# CTRL_MODULE_CORE register map
Vendor: Texas Instruments
Registers are 32-bit, access per field, reset 0x0 unless marked. A register's access mark holds for its fields unless they carry their own. Offsets are as the file gives them; [hi:lo] are bit positions.

## CTRL_MODULE_CORE (part 3 of 12)
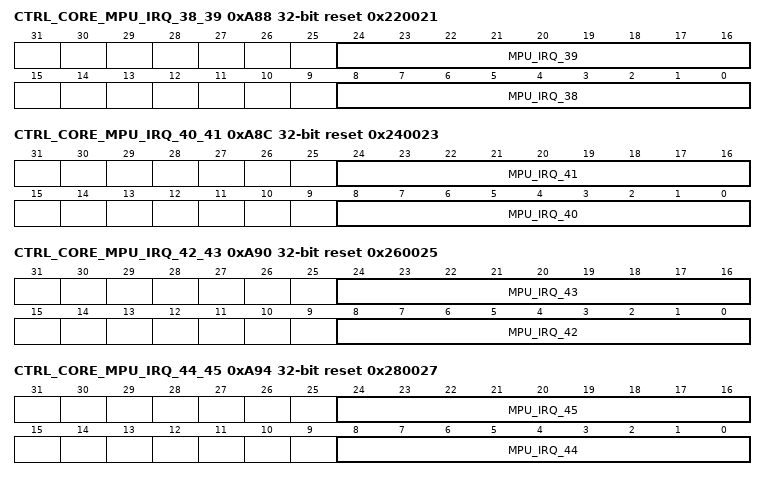
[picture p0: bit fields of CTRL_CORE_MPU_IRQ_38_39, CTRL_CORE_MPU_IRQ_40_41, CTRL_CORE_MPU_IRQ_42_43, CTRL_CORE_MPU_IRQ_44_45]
0xA88 CTRL_CORE_MPU_IRQ_38_39 reset 0x220021
  [24:16] MPU_IRQ_39 rw, [8:0] MPU_IRQ_38 rw
0xA8C CTRL_CORE_MPU_IRQ_40_41 reset 0x240023
  [24:16] MPU_IRQ_41 rw, [8:0] MPU_IRQ_40 rw
0xA90 CTRL_CORE_MPU_IRQ_42_43 reset 0x260025
  [24:16] MPU_IRQ_43 rw, [8:0] MPU_IRQ_42 rw
0xA94 CTRL_CORE_MPU_IRQ_44_45 reset 0x280027
  [24:16] MPU_IRQ_45 rw, [8:0] MPU_IRQ_44 rw
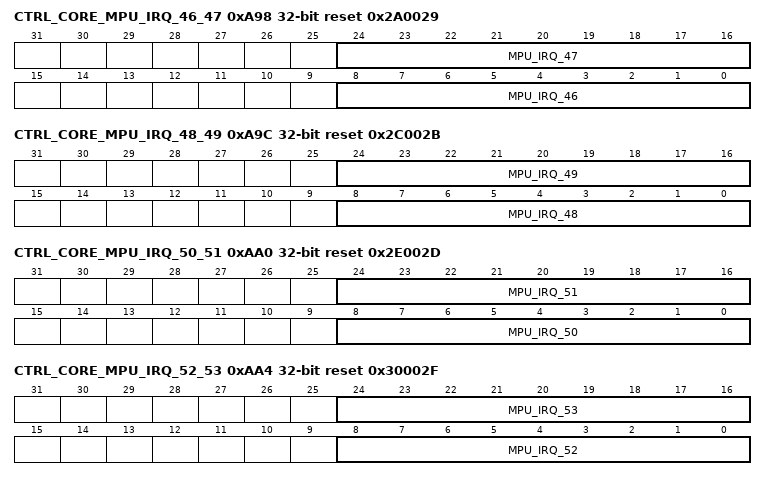
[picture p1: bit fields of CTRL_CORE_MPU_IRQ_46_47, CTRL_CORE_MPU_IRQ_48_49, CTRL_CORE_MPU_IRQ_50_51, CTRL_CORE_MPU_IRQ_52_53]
0xA98 CTRL_CORE_MPU_IRQ_46_47 reset 0x2A0029
  [24:16] MPU_IRQ_47 rw, [8:0] MPU_IRQ_46 rw
0xA9C CTRL_CORE_MPU_IRQ_48_49 reset 0x2C002B
  [24:16] MPU_IRQ_49 rw, [8:0] MPU_IRQ_48 rw
0xAA0 CTRL_CORE_MPU_IRQ_50_51 reset 0x2E002D
  [24:16] MPU_IRQ_51 rw, [8:0] MPU_IRQ_50 rw
0xAA4 CTRL_CORE_MPU_IRQ_52_53 reset 0x30002F
  [24:16] MPU_IRQ_53 rw, [8:0] MPU_IRQ_52 rw
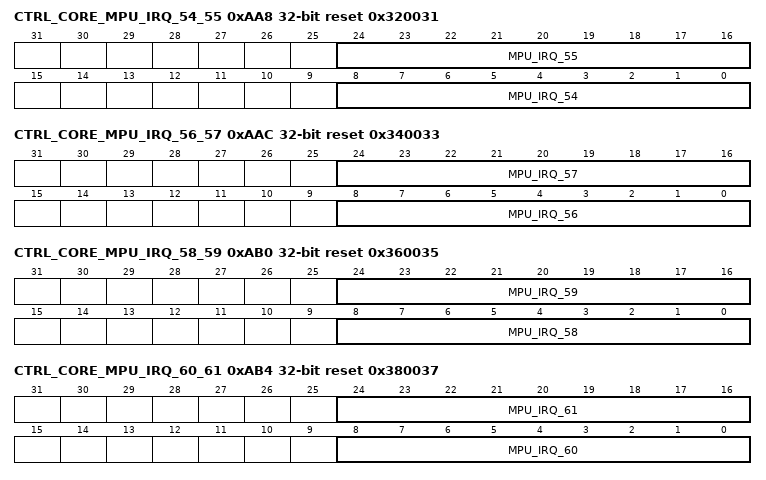
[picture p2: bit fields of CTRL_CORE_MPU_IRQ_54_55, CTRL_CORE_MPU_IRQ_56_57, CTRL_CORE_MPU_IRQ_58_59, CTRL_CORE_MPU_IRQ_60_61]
0xAA8 CTRL_CORE_MPU_IRQ_54_55 reset 0x320031
  [24:16] MPU_IRQ_55 rw, [8:0] MPU_IRQ_54 rw
0xAAC CTRL_CORE_MPU_IRQ_56_57 reset 0x340033
  [24:16] MPU_IRQ_57 rw, [8:0] MPU_IRQ_56 rw
0xAB0 CTRL_CORE_MPU_IRQ_58_59 reset 0x360035
  [24:16] MPU_IRQ_59 rw, [8:0] MPU_IRQ_58 rw
0xAB4 CTRL_CORE_MPU_IRQ_60_61 reset 0x380037
  [24:16] MPU_IRQ_61 rw, [8:0] MPU_IRQ_60 rw
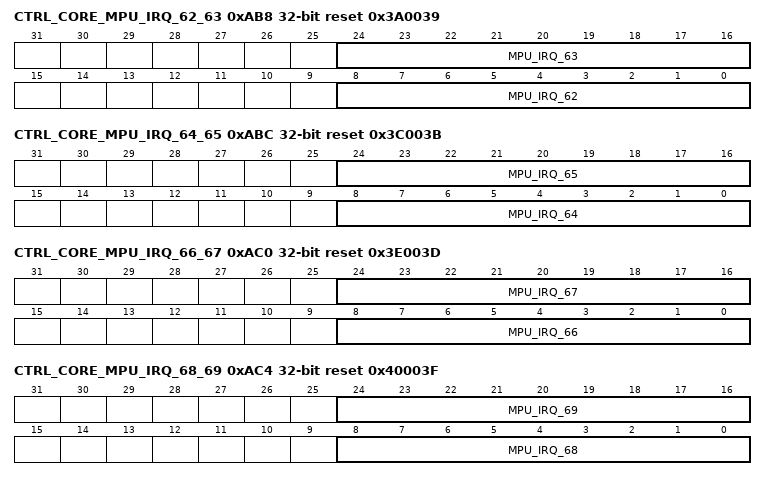
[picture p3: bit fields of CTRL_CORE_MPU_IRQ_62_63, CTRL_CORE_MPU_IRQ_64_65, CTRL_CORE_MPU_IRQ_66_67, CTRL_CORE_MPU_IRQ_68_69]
0xAB8 CTRL_CORE_MPU_IRQ_62_63 reset 0x3A0039
  [24:16] MPU_IRQ_63 rw, [8:0] MPU_IRQ_62 rw
0xABC CTRL_CORE_MPU_IRQ_64_65 reset 0x3C003B
  [24:16] MPU_IRQ_65 rw, [8:0] MPU_IRQ_64 rw
0xAC0 CTRL_CORE_MPU_IRQ_66_67 reset 0x3E003D
  [24:16] MPU_IRQ_67 rw, [8:0] MPU_IRQ_66 rw
0xAC4 CTRL_CORE_MPU_IRQ_68_69 reset 0x40003F
  [24:16] MPU_IRQ_69 rw, [8:0] MPU_IRQ_68 rw
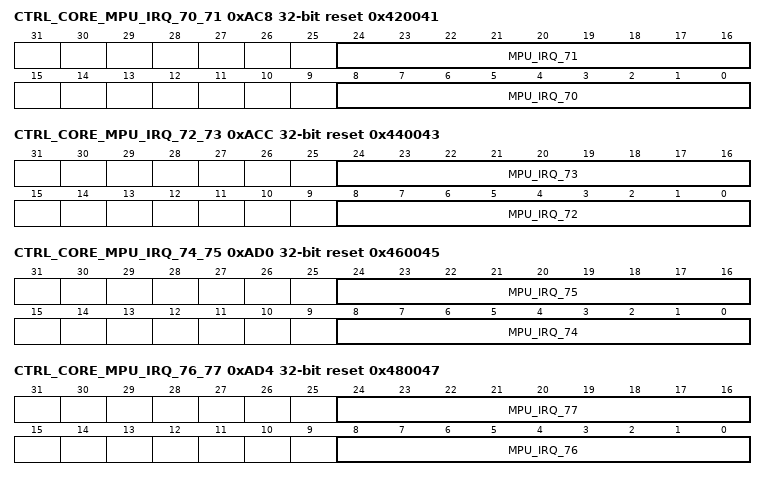
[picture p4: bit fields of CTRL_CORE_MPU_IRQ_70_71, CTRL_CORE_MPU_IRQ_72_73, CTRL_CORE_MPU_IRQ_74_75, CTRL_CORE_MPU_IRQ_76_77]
0xAC8 CTRL_CORE_MPU_IRQ_70_71 reset 0x420041
  [24:16] MPU_IRQ_71 rw, [8:0] MPU_IRQ_70 rw
0xACC CTRL_CORE_MPU_IRQ_72_73 reset 0x440043
  [24:16] MPU_IRQ_73 rw, [8:0] MPU_IRQ_72 rw
0xAD0 CTRL_CORE_MPU_IRQ_74_75 reset 0x460045
  [24:16] MPU_IRQ_75 rw, [8:0] MPU_IRQ_74 rw
0xAD4 CTRL_CORE_MPU_IRQ_76_77 reset 0x480047
  [24:16] MPU_IRQ_77 rw, [8:0] MPU_IRQ_76 rw
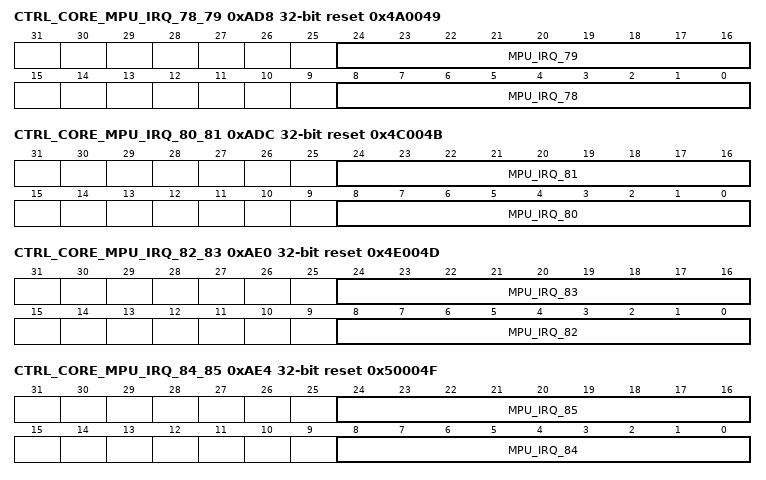
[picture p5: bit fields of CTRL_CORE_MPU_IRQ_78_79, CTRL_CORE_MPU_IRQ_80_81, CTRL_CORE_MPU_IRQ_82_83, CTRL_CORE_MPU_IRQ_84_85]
0xAD8 CTRL_CORE_MPU_IRQ_78_79 reset 0x4A0049
  [24:16] MPU_IRQ_79 rw, [8:0] MPU_IRQ_78 rw
0xADC CTRL_CORE_MPU_IRQ_80_81 reset 0x4C004B
  [24:16] MPU_IRQ_81 rw, [8:0] MPU_IRQ_80 rw
0xAE0 CTRL_CORE_MPU_IRQ_82_83 reset 0x4E004D
  [24:16] MPU_IRQ_83 rw, [8:0] MPU_IRQ_82 rw
0xAE4 CTRL_CORE_MPU_IRQ_84_85 reset 0x50004F
  [24:16] MPU_IRQ_85 rw, [8:0] MPU_IRQ_84 rw
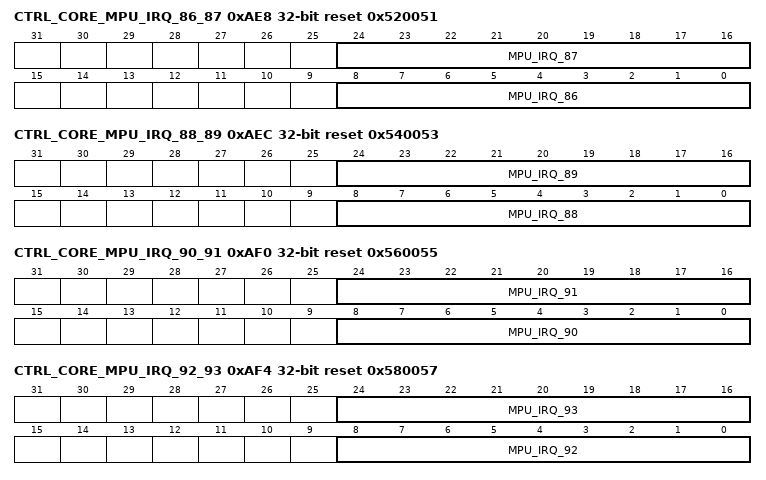
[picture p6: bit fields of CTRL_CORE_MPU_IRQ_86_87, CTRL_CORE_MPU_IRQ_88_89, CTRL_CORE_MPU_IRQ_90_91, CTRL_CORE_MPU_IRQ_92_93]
0xAE8 CTRL_CORE_MPU_IRQ_86_87 reset 0x520051
  [24:16] MPU_IRQ_87 rw, [8:0] MPU_IRQ_86 rw
0xAEC CTRL_CORE_MPU_IRQ_88_89 reset 0x540053
  [24:16] MPU_IRQ_89 rw, [8:0] MPU_IRQ_88 rw
0xAF0 CTRL_CORE_MPU_IRQ_90_91 reset 0x560055
  [24:16] MPU_IRQ_91 rw, [8:0] MPU_IRQ_90 rw
0xAF4 CTRL_CORE_MPU_IRQ_92_93 reset 0x580057
  [24:16] MPU_IRQ_93 rw, [8:0] MPU_IRQ_92 rw
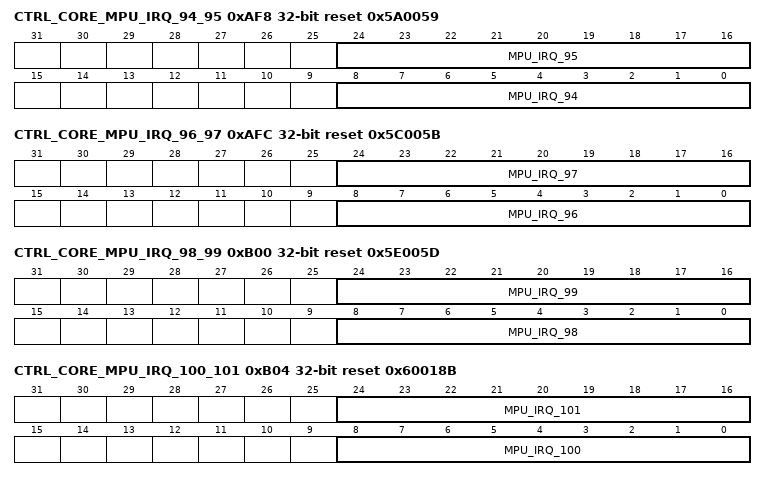
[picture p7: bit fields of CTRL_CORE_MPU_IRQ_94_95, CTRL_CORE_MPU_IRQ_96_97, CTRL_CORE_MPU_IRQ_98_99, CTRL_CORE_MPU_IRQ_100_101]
0xAF8 CTRL_CORE_MPU_IRQ_94_95 reset 0x5A0059
  [24:16] MPU_IRQ_95 rw, [8:0] MPU_IRQ_94 rw
0xAFC CTRL_CORE_MPU_IRQ_96_97 reset 0x5C005B
  [24:16] MPU_IRQ_97 rw, [8:0] MPU_IRQ_96 rw
0xB00 CTRL_CORE_MPU_IRQ_98_99 reset 0x5E005D
  [24:16] MPU_IRQ_99 rw, [8:0] MPU_IRQ_98 rw
0xB04 CTRL_CORE_MPU_IRQ_100_101 reset 0x60018B
  [24:16] MPU_IRQ_101 rw, [8:0] MPU_IRQ_100 rw
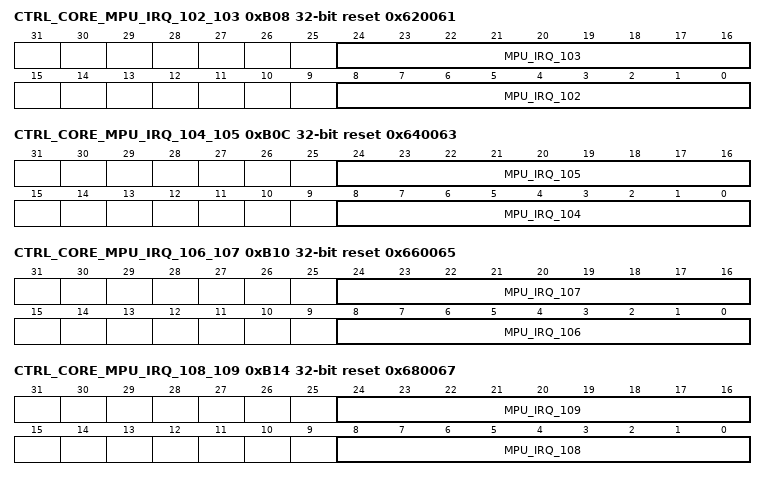
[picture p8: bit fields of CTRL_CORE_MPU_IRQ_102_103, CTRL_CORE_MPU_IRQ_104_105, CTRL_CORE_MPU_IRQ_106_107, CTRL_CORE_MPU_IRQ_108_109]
0xB08 CTRL_CORE_MPU_IRQ_102_103 reset 0x620061
  [24:16] MPU_IRQ_103 rw, [8:0] MPU_IRQ_102 rw
0xB0C CTRL_CORE_MPU_IRQ_104_105 reset 0x640063
  [24:16] MPU_IRQ_105 rw, [8:0] MPU_IRQ_104 rw
0xB10 CTRL_CORE_MPU_IRQ_106_107 reset 0x660065
  [24:16] MPU_IRQ_107 rw, [8:0] MPU_IRQ_106 rw
0xB14 CTRL_CORE_MPU_IRQ_108_109 reset 0x680067
  [24:16] MPU_IRQ_109 rw, [8:0] MPU_IRQ_108 rw
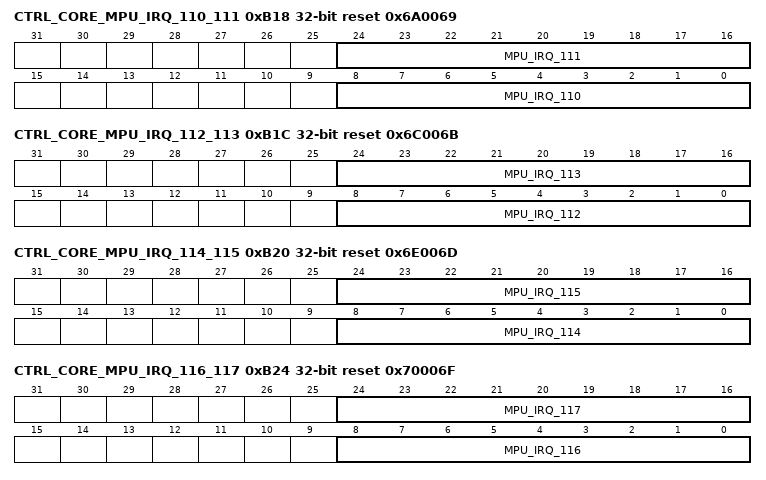
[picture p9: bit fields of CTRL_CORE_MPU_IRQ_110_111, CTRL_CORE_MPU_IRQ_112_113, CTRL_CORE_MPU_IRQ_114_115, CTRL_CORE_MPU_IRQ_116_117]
0xB18 CTRL_CORE_MPU_IRQ_110_111 reset 0x6A0069
  [24:16] MPU_IRQ_111 rw, [8:0] MPU_IRQ_110 rw
0xB1C CTRL_CORE_MPU_IRQ_112_113 reset 0x6C006B
  [24:16] MPU_IRQ_113 rw, [8:0] MPU_IRQ_112 rw
0xB20 CTRL_CORE_MPU_IRQ_114_115 reset 0x6E006D
  [24:16] MPU_IRQ_115 rw, [8:0] MPU_IRQ_114 rw
0xB24 CTRL_CORE_MPU_IRQ_116_117 reset 0x70006F
  [24:16] MPU_IRQ_117 rw, [8:0] MPU_IRQ_116 rw
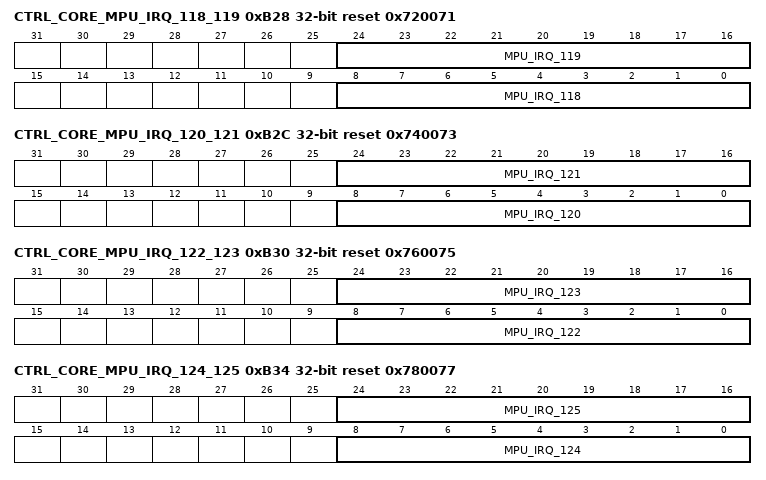
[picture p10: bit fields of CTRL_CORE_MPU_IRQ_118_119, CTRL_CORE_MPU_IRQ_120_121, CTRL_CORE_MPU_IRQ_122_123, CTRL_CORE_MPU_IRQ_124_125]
0xB28 CTRL_CORE_MPU_IRQ_118_119 reset 0x720071
  [24:16] MPU_IRQ_119 rw, [8:0] MPU_IRQ_118 rw
0xB2C CTRL_CORE_MPU_IRQ_120_121 reset 0x740073
  [24:16] MPU_IRQ_121 rw, [8:0] MPU_IRQ_120 rw
0xB30 CTRL_CORE_MPU_IRQ_122_123 reset 0x760075
  [24:16] MPU_IRQ_123 rw, [8:0] MPU_IRQ_122 rw
0xB34 CTRL_CORE_MPU_IRQ_124_125 reset 0x780077
  [24:16] MPU_IRQ_125 rw, [8:0] MPU_IRQ_124 rw
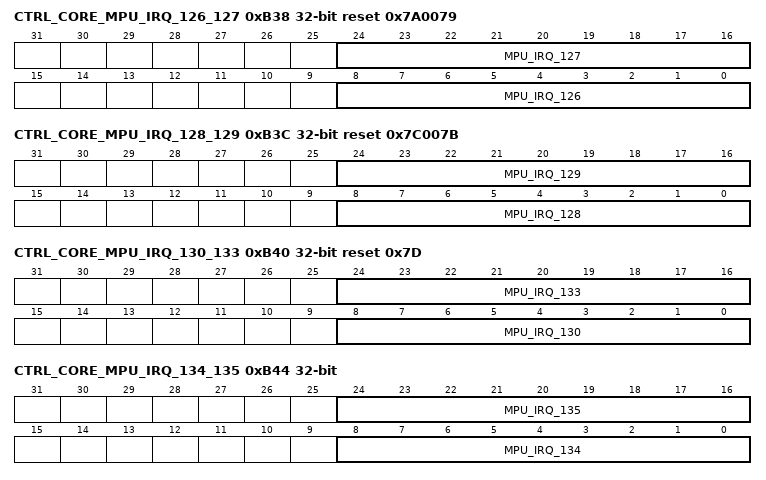
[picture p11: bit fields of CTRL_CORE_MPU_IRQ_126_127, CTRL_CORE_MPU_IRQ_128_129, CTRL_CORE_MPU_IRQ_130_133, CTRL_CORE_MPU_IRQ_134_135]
0xB38 CTRL_CORE_MPU_IRQ_126_127 reset 0x7A0079
  [24:16] MPU_IRQ_127 rw, [8:0] MPU_IRQ_126 rw
0xB3C CTRL_CORE_MPU_IRQ_128_129 reset 0x7C007B
  [24:16] MPU_IRQ_129 rw, [8:0] MPU_IRQ_128 rw
0xB40 CTRL_CORE_MPU_IRQ_130_133 reset 0x7D
  [24:16] MPU_IRQ_133 rw, [8:0] MPU_IRQ_130 rw
0xB44 CTRL_CORE_MPU_IRQ_134_135
  [24:16] MPU_IRQ_135 rw, [8:0] MPU_IRQ_134 rw
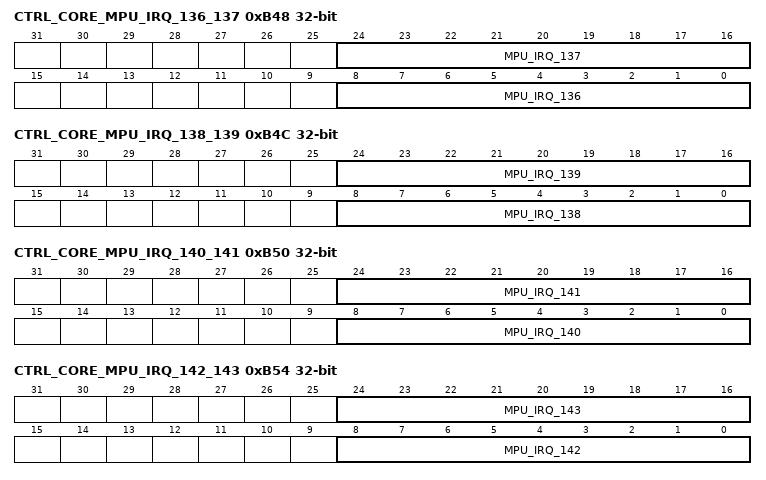
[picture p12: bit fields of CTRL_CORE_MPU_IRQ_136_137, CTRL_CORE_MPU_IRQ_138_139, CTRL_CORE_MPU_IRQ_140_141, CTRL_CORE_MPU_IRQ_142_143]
0xB48 CTRL_CORE_MPU_IRQ_136_137
  [24:16] MPU_IRQ_137 rw, [8:0] MPU_IRQ_136 rw
0xB4C CTRL_CORE_MPU_IRQ_138_139
  [24:16] MPU_IRQ_139 rw, [8:0] MPU_IRQ_138 rw
0xB50 CTRL_CORE_MPU_IRQ_140_141
  [24:16] MPU_IRQ_141 rw, [8:0] MPU_IRQ_140 rw
0xB54 CTRL_CORE_MPU_IRQ_142_143
  [24:16] MPU_IRQ_143 rw, [8:0] MPU_IRQ_142 rw
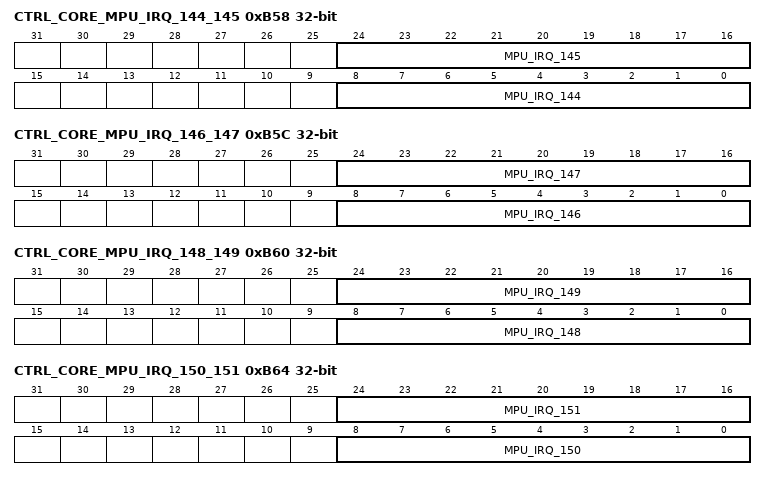
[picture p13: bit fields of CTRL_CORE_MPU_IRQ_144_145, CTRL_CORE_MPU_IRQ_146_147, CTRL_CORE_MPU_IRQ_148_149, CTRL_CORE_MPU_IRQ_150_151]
0xB58 CTRL_CORE_MPU_IRQ_144_145
  [24:16] MPU_IRQ_145 rw, [8:0] MPU_IRQ_144 rw
0xB5C CTRL_CORE_MPU_IRQ_146_147
  [24:16] MPU_IRQ_147 rw, [8:0] MPU_IRQ_146 rw
0xB60 CTRL_CORE_MPU_IRQ_148_149
  [24:16] MPU_IRQ_149 rw, [8:0] MPU_IRQ_148 rw
0xB64 CTRL_CORE_MPU_IRQ_150_151
  [24:16] MPU_IRQ_151 rw, [8:0] MPU_IRQ_150 rw
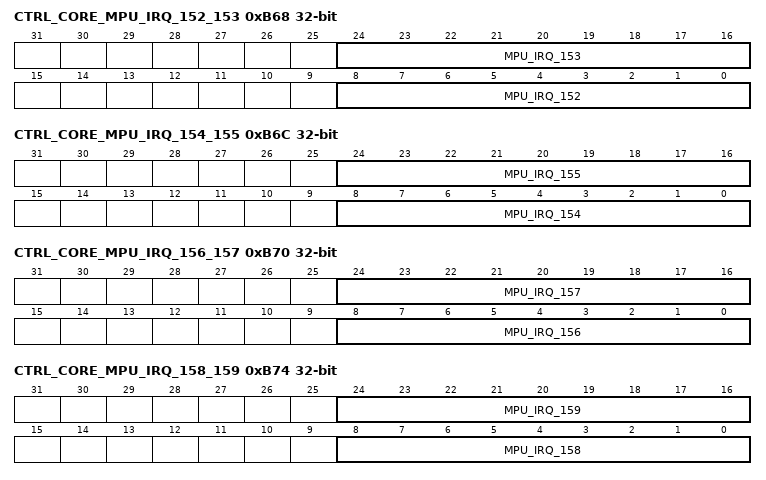
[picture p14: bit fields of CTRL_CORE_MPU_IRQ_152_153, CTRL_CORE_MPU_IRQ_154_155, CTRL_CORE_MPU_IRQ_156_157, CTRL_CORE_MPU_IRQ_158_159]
0xB68 CTRL_CORE_MPU_IRQ_152_153
  [24:16] MPU_IRQ_153 rw, [8:0] MPU_IRQ_152 rw
0xB6C CTRL_CORE_MPU_IRQ_154_155
  [24:16] MPU_IRQ_155 rw, [8:0] MPU_IRQ_154 rw
0xB70 CTRL_CORE_MPU_IRQ_156_157
  [24:16] MPU_IRQ_157 rw, [8:0] MPU_IRQ_156 rw
0xB74 CTRL_CORE_MPU_IRQ_158_159
  [24:16] MPU_IRQ_159 rw, [8:0] MPU_IRQ_158 rw
0xB78 CTRL_CORE_DMA_SYSTEM_DREQ_0_1 reset 0x20001
  [23:16] DMA_SYSTEM_DREQ_1_IRQ_1 rw, [7:0] DMA_SYSTEM_DREQ_0_IRQ_0 rw
0xB7C CTRL_CORE_DMA_SYSTEM_DREQ_2_3 reset 0x40003
  [23:16] DMA_SYSTEM_DREQ_3_IRQ_3 rw, [7:0] DMA_SYSTEM_DREQ_2_IRQ_2 rw
0xB80 CTRL_CORE_DMA_SYSTEM_DREQ_4_5 reset 0x60005
  [23:16] DMA_SYSTEM_DREQ_5_IRQ_5 rw, [7:0] DMA_SYSTEM_DREQ_4_IRQ_4 rw
0xB84 CTRL_CORE_DMA_SYSTEM_DREQ_6_7 reset 0x80007
  [23:16] DMA_SYSTEM_DREQ_7_IRQ_7 rw, [7:0] DMA_SYSTEM_DREQ_6_IRQ_6 rw
0xB88 CTRL_CORE_DMA_SYSTEM_DREQ_8_9 reset 0xA0009
  [23:16] DMA_SYSTEM_DREQ_9_IRQ_9 rw, [7:0] DMA_SYSTEM_DREQ_8_IRQ_8 rw
0xB8C CTRL_CORE_DMA_SYSTEM_DREQ_10_11 reset 0xC000B
  [23:16] DMA_SYSTEM_DREQ_11_IRQ_11 rw, [7:0] DMA_SYSTEM_DREQ_10_IRQ_10 rw
0xB90 CTRL_CORE_DMA_SYSTEM_DREQ_12_13 reset 0xE000D
  [23:16] DMA_SYSTEM_DREQ_13_IRQ_13 rw, [7:0] DMA_SYSTEM_DREQ_12_IRQ_12 rw
0xB94 CTRL_CORE_DMA_SYSTEM_DREQ_14_15 reset 0x10000F
  [23:16] DMA_SYSTEM_DREQ_15_IRQ_15 rw, [7:0] DMA_SYSTEM_DREQ_14_IRQ_14 rw
0xB98 CTRL_CORE_DMA_SYSTEM_DREQ_16_17 reset 0x120011
  [23:16] DMA_SYSTEM_DREQ_17_IRQ_17 rw, [7:0] DMA_SYSTEM_DREQ_16_IRQ_16 rw
0xB9C CTRL_CORE_DMA_SYSTEM_DREQ_18_19 reset 0x140013
  [23:16] DMA_SYSTEM_DREQ_19_IRQ_19 rw, [7:0] DMA_SYSTEM_DREQ_18_IRQ_18 rw
0xBA0 CTRL_CORE_DMA_SYSTEM_DREQ_20_21 reset 0x160015
  [23:16] DMA_SYSTEM_DREQ_21_IRQ_21 rw, [7:0] DMA_SYSTEM_DREQ_20_IRQ_20 rw
0xBA4 CTRL_CORE_DMA_SYSTEM_DREQ_22_23 reset 0x180017
  [23:16] DMA_SYSTEM_DREQ_23_IRQ_23 rw, [7:0] DMA_SYSTEM_DREQ_22_IRQ_22 rw
0xBA8 CTRL_CORE_DMA_SYSTEM_DREQ_24_25 reset 0x1A0019
  [23:16] DMA_SYSTEM_DREQ_25_IRQ_25 rw, [7:0] DMA_SYSTEM_DREQ_24_IRQ_24 rw
0xBAC CTRL_CORE_DMA_SYSTEM_DREQ_26_27 reset 0x1C001B
  [23:16] DMA_SYSTEM_DREQ_27_IRQ_27 rw, [7:0] DMA_SYSTEM_DREQ_26_IRQ_26 rw
0xBB0 CTRL_CORE_DMA_SYSTEM_DREQ_28_29 reset 0x1E001D
  [23:16] DMA_SYSTEM_DREQ_29_IRQ_29 rw, [7:0] DMA_SYSTEM_DREQ_28_IRQ_28 rw
0xBB4 CTRL_CORE_DMA_SYSTEM_DREQ_30_31 reset 0x20001F
  [23:16] DMA_SYSTEM_DREQ_31_IRQ_31 rw, [7:0] DMA_SYSTEM_DREQ_30_IRQ_30 rw
0xBB8 CTRL_CORE_DMA_SYSTEM_DREQ_32_33 reset 0x220021
  [23:16] DMA_SYSTEM_DREQ_33_IRQ_33 rw, [7:0] DMA_SYSTEM_DREQ_32_IRQ_32 rw
0xBBC CTRL_CORE_DMA_SYSTEM_DREQ_34_35 reset 0x240023
  [23:16] DMA_SYSTEM_DREQ_35_IRQ_35 rw, [7:0] DMA_SYSTEM_DREQ_34_IRQ_34 rw
0xBC0 CTRL_CORE_DMA_SYSTEM_DREQ_36_37 reset 0x260025
  [23:16] DMA_SYSTEM_DREQ_37_IRQ_37 rw, [7:0] DMA_SYSTEM_DREQ_36_IRQ_36 rw
0xBC4 CTRL_CORE_DMA_SYSTEM_DREQ_38_39 reset 0x280027
  [23:16] DMA_SYSTEM_DREQ_39_IRQ_39 rw, [7:0] DMA_SYSTEM_DREQ_38_IRQ_38 rw
0xBC8 CTRL_CORE_DMA_SYSTEM_DREQ_40_41 reset 0x2A0029
  [23:16] DMA_SYSTEM_DREQ_41_IRQ_41 rw, [7:0] DMA_SYSTEM_DREQ_40_IRQ_40 rw
0xBCC CTRL_CORE_DMA_SYSTEM_DREQ_42_43 reset 0x2C002B
  [23:16] DMA_SYSTEM_DREQ_43_IRQ_43 rw, [7:0] DMA_SYSTEM_DREQ_42_IRQ_42 rw
0xBD0 CTRL_CORE_DMA_SYSTEM_DREQ_44_45 reset 0x2E002D
  [23:16] DMA_SYSTEM_DREQ_45_IRQ_45 rw, [7:0] DMA_SYSTEM_DREQ_44_IRQ_44 rw
0xBD4 CTRL_CORE_DMA_SYSTEM_DREQ_46_47 reset 0x30002F
  [23:16] DMA_SYSTEM_DREQ_47_IRQ_47 rw, [7:0] DMA_SYSTEM_DREQ_46_IRQ_46 rw
0xBD8 CTRL_CORE_DMA_SYSTEM_DREQ_48_49 reset 0x320031
  [23:16] DMA_SYSTEM_DREQ_49_IRQ_49 rw, [7:0] DMA_SYSTEM_DREQ_48_IRQ_48 rw
0xBDC CTRL_CORE_DMA_SYSTEM_DREQ_50_51 reset 0x340033
  [23:16] DMA_SYSTEM_DREQ_51_IRQ_51 rw, [7:0] DMA_SYSTEM_DREQ_50_IRQ_50 rw
0xBE0 CTRL_CORE_DMA_SYSTEM_DREQ_52_53 reset 0x360035
  [23:16] DMA_SYSTEM_DREQ_53_IRQ_53 rw, [7:0] DMA_SYSTEM_DREQ_52_IRQ_52 rw
0xBE4 CTRL_CORE_DMA_SYSTEM_DREQ_54_55 reset 0x380037
  [23:16] DMA_SYSTEM_DREQ_55_IRQ_55 rw, [7:0] DMA_SYSTEM_DREQ_54_IRQ_54 rw
0xBE8 CTRL_CORE_DMA_SYSTEM_DREQ_56_57 reset 0x3A0039
  [23:16] DMA_SYSTEM_DREQ_57_IRQ_57 rw, [7:0] DMA_SYSTEM_DREQ_56_IRQ_56 rw
0xBEC CTRL_CORE_DMA_SYSTEM_DREQ_58_59 reset 0x3C003B
  [23:16] DMA_SYSTEM_DREQ_59_IRQ_59 rw, [7:0] DMA_SYSTEM_DREQ_58_IRQ_58 rw
0xBF0 CTRL_CORE_DMA_SYSTEM_DREQ_60_61 reset 0x3E003D
  [23:16] DMA_SYSTEM_DREQ_61_IRQ_61 rw, [7:0] DMA_SYSTEM_DREQ_60_IRQ_60 rw
0xBF4 CTRL_CORE_DMA_SYSTEM_DREQ_62_63 reset 0x40003F
  [23:16] DMA_SYSTEM_DREQ_63_IRQ_63 rw, [7:0] DMA_SYSTEM_DREQ_62_IRQ_62 rw
0xBF8 CTRL_CORE_DMA_SYSTEM_DREQ_64_65 reset 0x420041
  [23:16] DMA_SYSTEM_DREQ_65_IRQ_65 rw, [7:0] DMA_SYSTEM_DREQ_64_IRQ_64 rw
0xBFC CTRL_CORE_DMA_SYSTEM_DREQ_66_67 reset 0x440043
  [23:16] DMA_SYSTEM_DREQ_67_IRQ_67 rw, [7:0] DMA_SYSTEM_DREQ_66_IRQ_66 rw
0xC00 CTRL_CORE_DMA_SYSTEM_DREQ_68_69 reset 0x460045
  [23:16] DMA_SYSTEM_DREQ_69_IRQ_69 rw, [7:0] DMA_SYSTEM_DREQ_68_IRQ_68 rw
0xC04 CTRL_CORE_DMA_SYSTEM_DREQ_70_71 reset 0x480047
  [23:16] DMA_SYSTEM_DREQ_71_IRQ_71 rw, [7:0] DMA_SYSTEM_DREQ_70_IRQ_70 rw
0xC08 CTRL_CORE_DMA_SYSTEM_DREQ_72_73 reset 0x4A0049
  [23:16] DMA_SYSTEM_DREQ_73_IRQ_73 rw, [7:0] DMA_SYSTEM_DREQ_72_IRQ_72 rw
0xC0C CTRL_CORE_DMA_SYSTEM_DREQ_74_75 reset 0x4C004B
  [23:16] DMA_SYSTEM_DREQ_75_IRQ_75 rw, [7:0] DMA_SYSTEM_DREQ_74_IRQ_74 rw
0xC10 CTRL_CORE_DMA_SYSTEM_DREQ_76_77 reset 0x4E004D
  [23:16] DMA_SYSTEM_DREQ_77_IRQ_77 rw, [7:0] DMA_SYSTEM_DREQ_76_IRQ_76 rw
0xC14 CTRL_CORE_DMA_SYSTEM_DREQ_78_79 reset 0x50004F
  [23:16] DMA_SYSTEM_DREQ_79_IRQ_79 rw, [7:0] DMA_SYSTEM_DREQ_78_IRQ_78 rw
0xC18 CTRL_CORE_DMA_SYSTEM_DREQ_80_81 reset 0x520051
  [23:16] DMA_SYSTEM_DREQ_81_IRQ_81 rw, [7:0] DMA_SYSTEM_DREQ_80_IRQ_80 rw
0xC1C CTRL_CORE_DMA_SYSTEM_DREQ_82_83 reset 0x540053
  [23:16] DMA_SYSTEM_DREQ_83_IRQ_83 rw, [7:0] DMA_SYSTEM_DREQ_82_IRQ_82 rw
0xC20 CTRL_CORE_DMA_SYSTEM_DREQ_84_85 reset 0x560055
  [23:16] DMA_SYSTEM_DREQ_85_IRQ_85 rw, [7:0] DMA_SYSTEM_DREQ_84_IRQ_84 rw
0xC24 CTRL_CORE_DMA_SYSTEM_DREQ_86_87 reset 0x580057
  [23:16] DMA_SYSTEM_DREQ_87_IRQ_87 rw, [7:0] DMA_SYSTEM_DREQ_86_IRQ_86 rw
0xC28 CTRL_CORE_DMA_SYSTEM_DREQ_88_89 reset 0x5A0059
  [23:16] DMA_SYSTEM_DREQ_89_IRQ_89 rw, [7:0] DMA_SYSTEM_DREQ_88_IRQ_88 rw
0xC2C CTRL_CORE_DMA_SYSTEM_DREQ_90_91 reset 0x5C005B
  [23:16] DMA_SYSTEM_DREQ_91_IRQ_91 rw, [7:0] DMA_SYSTEM_DREQ_90_IRQ_90 rw
0xC30 CTRL_CORE_DMA_SYSTEM_DREQ_92_93 reset 0x5E005D
  [23:16] DMA_SYSTEM_DREQ_93_IRQ_93 rw, [7:0] DMA_SYSTEM_DREQ_92_IRQ_92 rw
0xC34 CTRL_CORE_DMA_SYSTEM_DREQ_94_95 reset 0x60005F
  [23:16] DMA_SYSTEM_DREQ_95_IRQ_95 rw, [7:0] DMA_SYSTEM_DREQ_94_IRQ_94 rw
0xC38 CTRL_CORE_DMA_SYSTEM_DREQ_96_97 reset 0x620061
  [23:16] DMA_SYSTEM_DREQ_97_IRQ_97 rw, [7:0] DMA_SYSTEM_DREQ_96_IRQ_96 rw
0xC3C CTRL_CORE_DMA_SYSTEM_DREQ_98_99 reset 0x640063
  [23:16] DMA_SYSTEM_DREQ_99_IRQ_99 rw, [7:0] DMA_SYSTEM_DREQ_98_IRQ_98 rw
0xC40 CTRL_CORE_DMA_SYSTEM_DREQ_100_101 reset 0x660065
  [23:16] DMA_SYSTEM_DREQ_101_IRQ_101 rw, [7:0] DMA_SYSTEM_DREQ_100_IRQ_100 rw
0xC44 CTRL_CORE_DMA_SYSTEM_DREQ_102_103 reset 0x680067
  [23:16] DMA_SYSTEM_DREQ_103_IRQ_103 rw, [7:0] DMA_SYSTEM_DREQ_102_IRQ_102 rw
0xC48 CTRL_CORE_DMA_SYSTEM_DREQ_104_105 reset 0x6A0069
  [23:16] DMA_SYSTEM_DREQ_105_IRQ_105 rw, [7:0] DMA_SYSTEM_DREQ_104_IRQ_104 rw
0xC4C CTRL_CORE_DMA_SYSTEM_DREQ_106_107 reset 0x6C006B
  [23:16] DMA_SYSTEM_DREQ_107_IRQ_107 rw, [7:0] DMA_SYSTEM_DREQ_106_IRQ_106 rw
0xC50 CTRL_CORE_DMA_SYSTEM_DREQ_108_109 reset 0x6E006D
  [23:16] DMA_SYSTEM_DREQ_109_IRQ_109 rw, [7:0] DMA_SYSTEM_DREQ_108_IRQ_108 rw
0xC54 CTRL_CORE_DMA_SYSTEM_DREQ_110_111 reset 0x70006F
  [23:16] DMA_SYSTEM_DREQ_111_IRQ_111 rw, [7:0] DMA_SYSTEM_DREQ_110_IRQ_110 rw
0xC58 CTRL_CORE_DMA_SYSTEM_DREQ_112_113 reset 0x720071
  [23:16] DMA_SYSTEM_DREQ_113_IRQ_113 rw, [7:0] DMA_SYSTEM_DREQ_112_IRQ_112 rw
0xC5C CTRL_CORE_DMA_SYSTEM_DREQ_114_115 reset 0x740073
  [23:16] DMA_SYSTEM_DREQ_115_IRQ_115 rw, [7:0] DMA_SYSTEM_DREQ_114_IRQ_114 rw
0xC60 CTRL_CORE_DMA_SYSTEM_DREQ_116_117 reset 0x760075
  [23:16] DMA_SYSTEM_DREQ_117_IRQ_117 rw, [7:0] DMA_SYSTEM_DREQ_116_IRQ_116 rw
0xC64 CTRL_CORE_DMA_SYSTEM_DREQ_118_119 reset 0x780077
  [23:16] DMA_SYSTEM_DREQ_119_IRQ_119 rw, [7:0] DMA_SYSTEM_DREQ_118_IRQ_118 rw
0xC68 CTRL_CORE_DMA_SYSTEM_DREQ_120_121 reset 0x7A0079
  [23:16] DMA_SYSTEM_DREQ_121_IRQ_121 rw, [7:0] DMA_SYSTEM_DREQ_120_IRQ_120 rw
0xC6C CTRL_CORE_DMA_SYSTEM_DREQ_122_123 reset 0x7C007B
  [23:16] DMA_SYSTEM_DREQ_123_IRQ_123 rw, [7:0] DMA_SYSTEM_DREQ_122_IRQ_122 rw
0xC70 CTRL_CORE_DMA_SYSTEM_DREQ_124_125 reset 0x7E007D
  [23:16] DMA_SYSTEM_DREQ_125_IRQ_125 rw, [7:0] DMA_SYSTEM_DREQ_124_IRQ_124 rw
0xC74 CTRL_CORE_DMA_SYSTEM_DREQ_126_127 reset 0x7F
  [7:0] DMA_SYSTEM_DREQ_126_IRQ_126 rw
0xC78 CTRL_CORE_DMA_EDMA_DREQ_0_1 reset 0x20001
  [23:16] DMA_EDMA_DREQ_1_IRQ_1 rw, [7:0] DMA_EDMA_DREQ_0_IRQ_0 rw
0xC7C CTRL_CORE_DMA_EDMA_DREQ_2_3 reset 0x40003
  [23:16] DMA_EDMA_DREQ_3_IRQ_3 rw, [7:0] DMA_EDMA_DREQ_2_IRQ_2 rw
0xC80 CTRL_CORE_DMA_EDMA_DREQ_4_5 reset 0x60005
  [23:16] DMA_EDMA_DREQ_5_IRQ_5 rw, [7:0] DMA_EDMA_DREQ_4_IRQ_4 rw
0xC84 CTRL_CORE_DMA_EDMA_DREQ_6_7 reset 0x80007
  [23:16] DMA_EDMA_DREQ_7_IRQ_7 rw, [7:0] DMA_EDMA_DREQ_6_IRQ_6 rw
0xC88 CTRL_CORE_DMA_EDMA_DREQ_8_9 reset 0xA0009
  [23:16] DMA_EDMA_DREQ_9_IRQ_9 rw, [7:0] DMA_EDMA_DREQ_8_IRQ_8 rw
0xC8C CTRL_CORE_DMA_EDMA_DREQ_10_11 reset 0xC000B
  [23:16] DMA_EDMA_DREQ_11_IRQ_11 rw, [7:0] DMA_EDMA_DREQ_10_IRQ_10 rw
0xC90 CTRL_CORE_DMA_EDMA_DREQ_12_13 reset 0xE000D
  [23:16] DMA_EDMA_DREQ_13_IRQ_13 rw, [7:0] DMA_EDMA_DREQ_12_IRQ_12 rw
0xC94 CTRL_CORE_DMA_EDMA_DREQ_14_15 reset 0x10000F
  [23:16] DMA_EDMA_DREQ_15_IRQ_15 rw, [7:0] DMA_EDMA_DREQ_14_IRQ_14 rw
0xC98 CTRL_CORE_DMA_EDMA_DREQ_16_17 reset 0x120011
  [23:16] DMA_EDMA_DREQ_17_IRQ_17 rw, [7:0] DMA_EDMA_DREQ_16_IRQ_16 rw
0xC9C CTRL_CORE_DMA_EDMA_DREQ_18_19 reset 0x140013
  [23:16] DMA_EDMA_DREQ_19_IRQ_19 rw, [7:0] DMA_EDMA_DREQ_18_IRQ_18 rw
0xCA0 CTRL_CORE_DMA_EDMA_DREQ_20_21 reset 0x160015
  [23:16] DMA_EDMA_DREQ_21_IRQ_21 rw, [7:0] DMA_EDMA_DREQ_20_IRQ_20 rw
0xCA4 CTRL_CORE_DMA_EDMA_DREQ_22_23 reset 0x180017
  [23:16] DMA_EDMA_DREQ_23_IRQ_23 rw, [7:0] DMA_EDMA_DREQ_22_IRQ_22 rw
0xCA8 CTRL_CORE_DMA_EDMA_DREQ_24_25 reset 0x1A0019
  [23:16] DMA_EDMA_DREQ_25_IRQ_25 rw, [7:0] DMA_EDMA_DREQ_24_IRQ_24 rw
0xCAC CTRL_CORE_DMA_EDMA_DREQ_26_27 reset 0x1C001B
  [23:16] DMA_EDMA_DREQ_27_IRQ_27 rw, [7:0] DMA_EDMA_DREQ_26_IRQ_26 rw
0xCB0 CTRL_CORE_DMA_EDMA_DREQ_28_29 reset 0x1E001D
  [23:16] DMA_EDMA_DREQ_29_IRQ_29 rw, [7:0] DMA_EDMA_DREQ_28_IRQ_28 rw
0xCB4 CTRL_CORE_DMA_EDMA_DREQ_30_31 reset 0x20001F
  [23:16] DMA_EDMA_DREQ_31_IRQ_31 rw, [7:0] DMA_EDMA_DREQ_30_IRQ_30 rw
0xCB8 CTRL_CORE_DMA_EDMA_DREQ_32_33 reset 0x220021
  [23:16] DMA_EDMA_DREQ_33_IRQ_33 rw, [7:0] DMA_EDMA_DREQ_32_IRQ_32 rw
0xCBC CTRL_CORE_DMA_EDMA_DREQ_34_35 reset 0x240023
  [23:16] DMA_EDMA_DREQ_35_IRQ_35 rw, [7:0] DMA_EDMA_DREQ_34_IRQ_34 rw
0xCC0 CTRL_CORE_DMA_EDMA_DREQ_36_37 reset 0x260025
  [23:16] DMA_EDMA_DREQ_37_IRQ_37 rw, [7:0] DMA_EDMA_DREQ_36_IRQ_36 rw
0xCC4 CTRL_CORE_DMA_EDMA_DREQ_38_39 reset 0x280027
  [23:16] DMA_EDMA_DREQ_39_IRQ_39 rw, [7:0] DMA_EDMA_DREQ_38_IRQ_38 rw
0xCC8 CTRL_CORE_DMA_EDMA_DREQ_40_41 reset 0x2A0029
  [23:16] DMA_EDMA_DREQ_41_IRQ_41 rw, [7:0] DMA_EDMA_DREQ_40_IRQ_40 rw
0xCCC CTRL_CORE_DMA_EDMA_DREQ_42_43 reset 0x2C002B
  [23:16] DMA_EDMA_DREQ_43_IRQ_43 rw, [7:0] DMA_EDMA_DREQ_42_IRQ_42 rw
0xCD0 CTRL_CORE_DMA_EDMA_DREQ_44_45 reset 0x2E002D
  [23:16] DMA_EDMA_DREQ_45_IRQ_45 rw, [7:0] DMA_EDMA_DREQ_44_IRQ_44 rw
0xCD4 CTRL_CORE_DMA_EDMA_DREQ_46_47 reset 0x30002F
  [23:16] DMA_EDMA_DREQ_47_IRQ_47 rw, [7:0] DMA_EDMA_DREQ_46_IRQ_46 rw
0xCD8 CTRL_CORE_DMA_EDMA_DREQ_48_49 reset 0x320031
  [23:16] DMA_EDMA_DREQ_49_IRQ_49 rw, [7:0] DMA_EDMA_DREQ_48_IRQ_48 rw
0xCDC CTRL_CORE_DMA_EDMA_DREQ_50_51 reset 0x340033
  [23:16] DMA_EDMA_DREQ_51_IRQ_51 rw, [7:0] DMA_EDMA_DREQ_50_IRQ_50 rw
0xCE0 CTRL_CORE_DMA_EDMA_DREQ_52_53 reset 0x360035
  [23:16] DMA_EDMA_DREQ_53_IRQ_53 rw, [7:0] DMA_EDMA_DREQ_52_IRQ_52 rw
0xCE4 CTRL_CORE_DMA_EDMA_DREQ_54_55 reset 0x380037
  [23:16] DMA_EDMA_DREQ_55_IRQ_55 rw, [7:0] DMA_EDMA_DREQ_54_IRQ_54 rw
0xCE8 CTRL_CORE_DMA_EDMA_DREQ_56_57 reset 0x3A0039
  [23:16] DMA_EDMA_DREQ_57_IRQ_57 rw, [7:0] DMA_EDMA_DREQ_56_IRQ_56 rw
0xCEC CTRL_CORE_DMA_EDMA_DREQ_58_59 reset 0x3C003B
  [23:16] DMA_EDMA_DREQ_59_IRQ_59 rw, [7:0] DMA_EDMA_DREQ_58_IRQ_58 rw
0xCF0 CTRL_CORE_DMA_EDMA_DREQ_60_61 reset 0x3E003D
  [23:16] DMA_EDMA_DREQ_61_IRQ_61 rw, [7:0] DMA_EDMA_DREQ_60_IRQ_60 rw
0xCF4 CTRL_CORE_DMA_EDMA_DREQ_62_63 reset 0x40003F
  [23:16] DMA_EDMA_DREQ_63_IRQ_63 rw, [7:0] DMA_EDMA_DREQ_62_IRQ_62 rw
0xCF8 CTRL_CORE_DMA_DSP1_DREQ_0_1 reset 0x810080
  [23:16] DMA_DSP1_DREQ_1_IRQ_1 rw, [7:0] DMA_DSP1_DREQ_0_IRQ_0 rw
0xCFC CTRL_CORE_DMA_DSP1_DREQ_2_3 reset 0x830082
  [23:16] DMA_DSP1_DREQ_3_IRQ_3 rw, [7:0] DMA_DSP1_DREQ_2_IRQ_2 rw
0xD00 CTRL_CORE_DMA_DSP1_DREQ_4_5 reset 0x850084
  [23:16] DMA_DSP1_DREQ_5_IRQ_5 rw, [7:0] DMA_DSP1_DREQ_4_IRQ_4 rw
0xD04 CTRL_CORE_DMA_DSP1_DREQ_6_7 reset 0x870086
  [23:16] DMA_DSP1_DREQ_7_IRQ_7 rw, [7:0] DMA_DSP1_DREQ_6_IRQ_6 rw
0xD08 CTRL_CORE_DMA_DSP1_DREQ_8_9 reset 0x890088
  [23:16] DMA_DSP1_DREQ_9_IRQ_9 rw, [7:0] DMA_DSP1_DREQ_8_IRQ_8 rw
0xD0C CTRL_CORE_DMA_DSP1_DREQ_10_11 reset 0x8B008A
  [23:16] DMA_DSP1_DREQ_11_IRQ_11 rw, [7:0] DMA_DSP1_DREQ_10_IRQ_10 rw
0xD10 CTRL_CORE_DMA_DSP1_DREQ_12_13 reset 0x8D008C
  [23:16] DMA_DSP1_DREQ_13_IRQ_13 rw, [7:0] DMA_DSP1_DREQ_12_IRQ_12 rw
0xD14 CTRL_CORE_DMA_DSP1_DREQ_14_15 reset 0x8F008E
  [23:16] DMA_DSP1_DREQ_15_IRQ_15 rw, [7:0] DMA_DSP1_DREQ_14_IRQ_14 rw
0xD18 CTRL_CORE_DMA_DSP1_DREQ_16_17 reset 0x9B009A
  [23:16] DMA_DSP1_DREQ_17_IRQ_17 rw, [7:0] DMA_DSP1_DREQ_16_IRQ_16 rw
0xD1C CTRL_CORE_DMA_DSP1_DREQ_18_19 reset 0x9D009C
  [23:16] DMA_DSP1_DREQ_19_IRQ_19 rw, [7:0] DMA_DSP1_DREQ_18_IRQ_18 rw
0xD20 CTRL_CORE_DMA_DSP2_DREQ_0_1 reset 0x810080
  [23:16] DMA_DSP2_DREQ_1_IRQ_1 rw, [7:0] DMA_DSP2_DREQ_0_IRQ_0 rw
0xD24 CTRL_CORE_DMA_DSP2_DREQ_2_3 reset 0x830082
  [23:16] DMA_DSP2_DREQ_3_IRQ_3 rw, [7:0] DMA_DSP2_DREQ_2_IRQ_2 rw
0xD28 CTRL_CORE_DMA_DSP2_DREQ_4_5 reset 0x850084
  [23:16] DMA_DSP2_DREQ_5_IRQ_5 rw, [7:0] DMA_DSP2_DREQ_4_IRQ_4 rw
0xD2C CTRL_CORE_DMA_DSP2_DREQ_6_7 reset 0x870086
  [23:16] DMA_DSP2_DREQ_7_IRQ_7 rw, [7:0] DMA_DSP2_DREQ_6_IRQ_6 rw
0xD30 CTRL_CORE_DMA_DSP2_DREQ_8_9 reset 0x890088
  [23:16] DMA_DSP2_DREQ_9_IRQ_9 rw, [7:0] DMA_DSP2_DREQ_8_IRQ_8 rw
0xD34 CTRL_CORE_DMA_DSP2_DREQ_10_11 reset 0x8B008A
  [23:16] DMA_DSP2_DREQ_11_IRQ_11 rw, [7:0] DMA_DSP2_DREQ_10_IRQ_10 rw
0xD38 CTRL_CORE_DMA_DSP2_DREQ_12_13 reset 0x8D008C
  [23:16] DMA_DSP2_DREQ_13_IRQ_13 rw, [7:0] DMA_DSP2_DREQ_12_IRQ_12 rw
0xD3C CTRL_CORE_DMA_DSP2_DREQ_14_15 reset 0x8F008E
  [23:16] DMA_DSP2_DREQ_15_IRQ_15 rw, [7:0] DMA_DSP2_DREQ_14_IRQ_14 rw
0xD40 CTRL_CORE_DMA_DSP2_DREQ_16_17 reset 0x9B009A
  [23:16] DMA_DSP2_DREQ_17_IRQ_17 rw, [7:0] DMA_DSP2_DREQ_16_IRQ_16 rw
0xD44 CTRL_CORE_DMA_DSP2_DREQ_18_19 reset 0x9D009C
  [23:16] DMA_DSP2_DREQ_19_IRQ_19 rw, [7:0] DMA_DSP2_DREQ_18_IRQ_18 rw
0xD4C CTRL_CORE_OVS_DMARQ_IO_MUX
  [15:8] OVS_DMARQ_IO_MUX_2 rw, [7:0] OVS_DMARQ_IO_MUX_1 rw
0xD50 CTRL_CORE_OVS_IRQ_IO_MUX
  [17:9] OVS_IRQ_IO_MUX_2 rw, [8:0] OVS_IRQ_IO_MUX_1 rw
0xE00 CTRL_CORE_CONTROL_PBIAS reset 0x200000 — PBIASLITE control
  [27] SDCARD_BIAS_PWRDNZ rw — PWRDNZ control to SDCARD BIAS 0x0 = This signal is used to protect SDCARD BIAS when VDDS is not stable 0x1 = SW keep this bit to 1'b1 after VDDS stabilizing
  [26] SDCARD_IO_PWRDNZ rw — PWRDNZ control to SDCARD IO 0x0 = This signal is used to protect SDCARD IOs when VDDS is not stable 0x1 = SW keep this bit to 1'b1 after VDDS stabilizing
  [25] SDCARD_BIAS_HIZ_MODE rw — HIZ_MODE from SDCARD PBIAS 0x0 = PBIAS in normal operation mode 0x1 = PBIAS output is in high impedance state
  [24] SDCARD_BIAS_SUPPLY_HI_OUT ro — SUPPLY_HI_OUT from SDCARD PBIAS 0x0 = VDDS = 1.8V 0x1 = VDDS = 3.3V
  [23] SDCARD_BIAS_VMODE_ERROR ro — VMODE ERROR from SDCARD PBIAS 0x0 = VMODE level is same as SUPPLY_HI_OUT 0x1 = VMODE level is not same as SUPPLY_HI_OUT
  [21] SDCARD_BIAS_VMODE rw — VMODE control to SDCARD PBIAS 0x0 = VDDS = 1.8V 0x1 = VDDS = 3.3V
0xE0C CTRL_CORE_CONTROL_HDMI_TX_PHY reset 0x10000000 — HDMI TX PHY control
  [30] HDMITXPHY_TXVALID rw — 0x1= Valid data on the HDMI_TXPHY input data interface , sampled on the rising edge of TMDSCLK
  [29] HDMITXPHY_ENBYPASSCLK rw — 0x1 = Enables the HFBYPASSCLK to be used in place of the HFBITCLK
  [28] HDMITXPHY_PD_PULLUPDET rw — 0x0 = Set this bit to 0x0 if RX connection is required to be detected, even when HDMI_TXPHY is powered down 0x1 = Disables the low power RX detection functionality
0xE1C CTRL_CORE_CONTROL_USB2PHYCORE reset 0x40000000 — This register is related to the USB2_PHY1.
  [31] USB2PHY_AUTORESUME_EN rw — Auto resume enable 0x0 = disable autoresume 0x1 = enable autoresume
  [30] USB2PHY_DISCHGDET rw — Disable charger detect 0x0 = charger detect function enabled 0x1 = charger detect function disabled
  [29] USB2PHY_GPIOMODE rw — GPIO mode 0x0 = USB mode enabled 0x1 = GPIO mode enabled
  [28] USB2PHY_CHG_DET_EXT_CTL rw — Charge detect external control 0x0 = charger detect internal state machine used 0x1 = charge detect statemachine is bypassed
  [27] USB2PHY_RDM_PD_CHGDET_EN rw — DM Pull down control 0x0 = PD disabled 0x1 = PD enabled
  [26] USB2PHY_RDP_PU_CHGDET_EN rw — DP Pull up control 0x0 = PU disabled 0x1 = PU enabled
  [25] USB2PHY_CHG_VSRC_EN rw — VSRC enable on DP line:Host charger case 0x0 = disable VSRC drive on DP 0x1 = drives VSRC 600mV on DP line
  [24] USB2PHY_CHG_ISINK_EN rw — ISINK enable on DM line:Host charger case 0x0 = disable the isink on DM 0x1 = enables the ISINK (100uA) on DM line
  [23:21] USB2PHY_CHG_DET_STATUS ro — Status of charger detection 0x0 = Wait state 0x1 = No contact 0x2 = PS/2 0x3 = Unknown error 0x4 = Dedicated charger 0x5 = HOST charger 0x6 = PC 0x7 = Interrupt
  [20] USB2PHY_CHG_DET_DM_COMP ro — Output of the comparator on DM during the resistor host detect protocol 0x0 = DM line is below 0.75V to 0.95V 0x1 = DM line is above 0.75V to 0.95V
  [19] USB2PHY_CHG_DET_DP_COMP ro — Output of the comparator on DP during the resistor host detect protocol 0x0 = DP line is below 0.75V to 0.95V 0x1 = DP line is above 0.75V to 0.95V
  [18] USB2PHY_DATADET ro — Output of the charger detect comparator 0x0 = DM line is below 0.25V to 0.4V 0x1 = DM line is above 0.25V to 0.4V
  [17] USB2PHY_SINKONDP rw — When '1' current sink is connected to DP instead of DM 0x0 = Default value 0x1 = enables the ISINK on DP instead of DM
  [16] USB2PHY_SRCONDM rw — When '1' voltage source is connected to DP instead of DM 0x0 = Default value 0x1 = enable the VSRC on DM instead of DP
  [15] USB2PHY_RESTARTCHGDET rw — restartchgdet = '1' for 1 msec cause the CD_START to reset 0x0 = Default value 0x1 = a high pulse of 1 msec causes the charger detect to restart on negative edge of restartchgdet
  [14] USB2PHY_CHGDETDONE ro — Status indicates that charger detection protocol is over 0x0 = charger detection protocol is not over 0x1 = charger detection protocol is over
  [13] USB2PHY_CHGDETECTED ro — Output of the charger detection protocol 0x0 = charger not detected 0x1 = charger detected
  [12] USB2PHY_MCPCPUEN rw — MCPC Pull up enable 0x0 = disable the MCPC pull up 0x1 = enable the 4.7K to10K pull up on receive line DP when datapolarityn is 0 and DM when datapolarityn is 1
  [11] USB2PHY_MCPCMODEEN rw — MCPC Mode enable 0x0 = disable MCPC mode 0x1 = enable MCPC mode
  [10] USB2PHY_RESETDONEMCLK ro — OCP reset status 0x0 = OCP domain is in reset 0x1 = OCP domain is out of reset
  [9] USB2PHY_UTMIRESETDONE ro — UTMI FSM reset status 0x0 = UTMI FSMs are in reset 0x1 = UTMI FSMs are out of reset
  [7] USB2PHY_DATAPOLARITYN rw — Data polarity 0x0 = DP functionality is on DP and DM funcationality is on DM 0x1 = DP functionality is on DM and DM functionality is on DP
  [6] USBDPLL_FREQLOCK ro — Status from USB DPLL
  [5] USB2PHY_RESETDONETCLK ro — resetdonetclk status from USB2PHY
0xE20 CTRL_CORE_CONTROL_HDMI_1 — HDMI pads control 1
  [31] HDMI_DDC_SDA_GLFENB rw — Active_high glitch free operation enable pin for hdmi_ddc_sda receiver
    0=DISABLE (Disabled); 1=ENABLE (Enabled)
  [30] HDMI_DDC_SDA_PULLUPRESX rw — Active_low internal pull_up resistor enabled for hdmi_ddc_sda
    0=ENABLE (Enabled); 1=DISABLE (Disabled)
  [29] HDMI_DDC_SCL_GLFENB rw — Active_high glitch free operation enable pin for hdmi_ddc_scl receiver
    0=DISABLE (Disabled); 1=ENABLE (Enabled)
  [28] HDMI_DDC_SCL_PULLUPRESX rw — Active_low internal pull_up resistor enabled for hdmi_ddc_scl
    0=ENABLE (Enabled); 1=DISABLE (Disabled)
  [27] HDMI_DDC_SDA_HSMODE rw — Active-high selection for I2C High-Speed mode
    0=DISABLE (Disabled); 1=ENABLE (Enabled)
  [26] HDMI_DDC_SCL_HSMODE rw — Active-high selection for I2C High-Speed mode
    0=DISABLE (Disabled); 1=ENABLE (Enabled)
0xE30 CTRL_CORE_CONTROL_DDRCACH1_0 rw reset 0x4A4A4A4A — ddrcaCH1 control
  [31:29] DDRCH1_PART0_I — PART0 Impedence control I[2:0] 0x0: Imp80 0x1: Imp60 0x2: Imp48 0x3: Imp40 0x4: Imp34 0x5: Reserved 0x6: Reserved 0x7: Reserved
  [28:26] DDRCH1_PART0_SR — PART0 Slew Rate control SR[2:0]. All 8 values are valid. 0x0: Fastest .... 0x7: Slowest
  [25:24] DDRCH1_PART0_WD — PART0 Weak driver control WD[1:0] -For single-ended operation: 0x0: Pull logic is disabled 0x1: Pull-up selected 0x2: Pull-down selected 0x3: Maintain the previous output value -For differential pair operation: 0x0: Pull logic is disabled 0x1: Pull-up selected for padp, pull-down selected for padn 0x2: Pull-down selected for padp, pull-up selected for padn 0x3: Maintain the previous output value
  [23:21] DDRCH1_PART5A_I — PART5A Impedence control I[2:0] 0x0: Imp80 0x1: Imp60 0x2: Imp48 0x3: Imp40 0x4: Imp34 0x5: Reserved 0x6: Reserved 0x7: Reserved
  [20:18] DDRCH1_PART5A_SR — PART5A Slew Rate control SR[2:0]. All 8 values are valid. 0x0: Fastest .... 0x7: Slowest
  [17:16] DDRCH1_PART5A_WD — PART5A Weak driver control WD[1:0] -For single-ended operation: 0x0: Pull logic is disabled 0x1: Pull-up selected 0x2: Pull-down selected 0x3: Maintain the previous output value -For differential pair operation: 0x0: Pull logic is disabled 0x1: Pull-up selected for padp, pull-down selected for padn 0x2: Pull-down selected for padp, pull-up selected for padn 0x3: Maintain the previous output value
  [15:13] DDRCH1_PART5B_I — PART5B Impedence control I[2:0] 0x0: Imp80 0x1: Imp60 0x2: Imp48 0x3: Imp40 0x4: Imp34 0x5: Reserved 0x6: Reserved 0x7: Reserved
  [12:10] DDRCH1_PART5B_SR — PART5B Slew Rate control SR[2:0]. All 8 values are valid. 0x0: Fastest .... 0x7: Slowest
  [9:8] DDRCH1_PART5B_WD — PART5B Weak driver control WD[1:0] -For single-ended operation: 0x0: Pull logic is disabled 0x1: Pull-up selected 0x2: Pull-down selected 0x3: Maintain the previous output value -For differential pair operation: 0x0: Pull logic is disabled 0x1: Pull-up selected for padp, pull-down selected for padn 0x2: Pull-down selected for padp, pull-up selected for padn 0x3: Maintain the previous output value
  [7:5] DDRCH1_PART6_I — PART6 Impedence control I[2:0] 0x0: Imp80 0x1: Imp60 0x2: Imp48 0x3: Imp40 0x4: Imp34 0x5: Reserved 0x6: Reserved 0x7: Reserved
  [4:2] DDRCH1_PART6_SR — PART6 Slew Rate control SR[2:0]. All 8 values are valid. 0x0: Fastest .... 0x7: Slowest
  [1:0] DDRCH1_PART6_WD — PART6 Weak driver control WD[1:0] -For single-ended operation: 0x0: Pull logic is disabled 0x1: Pull-up selected 0x2: Pull-down selected 0x3: Maintain the previous output value -For differential pair operation: 0x0: Pull logic is disabled 0x1: Pull-up selected for padp, pull-down selected for padn 0x2: Pull-down selected for padp, pull-up selected for padn 0x3: Maintain the previous output value
0xE34 CTRL_CORE_CONTROL_DDRCACH2_0 rw reset 0x4A4A4A4A — ddrcaCH2 control
  [31:29] DDRCH2_PART0_I — PART0 Impedence control I[2:0] 0x0: Imp80 0x1: Imp60 0x2: Imp48 0x3: Imp40 0x4: Imp34 0x5: Reserved 0x6: Reserved 0x7: Reserved
  [28:26] DDRCH2_PART0_SR — PART0 Slew Rate control SR[2:0]. All 8 values are valid. 0x0: Fastest .... 0x7: Slowest
  [25:24] DDRCH2_PART0_WD — PART0 Weak driver control WD[1:0] -For single-ended operation: 0x0: Pull logic is disabled 0x1: Pull-up selected 0x2: Pull-down selected 0x3: Maintain the previous output value -For differential pair operation: 0x0: Pull logic is disabled 0x1: Pull-up selected for padp, pull-down selected for padn 0x2: Pull-down selected for padp, pull-up selected for padn 0x3: Maintain the previous output value
  [23:21] DDRCH2_PART5A_I — PART5A Impedence control I[2:0] 0x0: Imp80 0x1: Imp60 0x2: Imp48 0x3: Imp40 0x4: Imp34 0x5: Reserved 0x6: Reserved 0x7: Reserved
  [20:18] DDRCH2_PART5A_SR — PART5A Slew Rate control SR[2:0]. All 8 values are valid. 0x0: Fastest .... 0x7: Slowest
  [17:16] DDRCH2_PART5A_WD — PART5A Weak driver control WD[1:0] -For single-ended operation: 0x0: Pull logic is disabled 0x1: Pull-up selected 0x2: Pull-down selected 0x3: Maintain the previous output value -For differential pair operation: 0x0: Pull logic is disabled 0x1: Pull-up selected for padp, pull-down selected for padn 0x2: Pull-down selected for padp, pull-up selected for padn 0x3: Maintain the previous output value
  [15:13] DDRCH2_PART5B_I — PART5B Impedence control I[2:0] 0x0: Imp80 0x1: Imp60 0x2: Imp48 0x3: Imp40 0x4: Imp34 0x5: Reserved 0x6: Reserved 0x7: Reserved
  [12:10] DDRCH2_PART5B_SR — PART5B Slew Rate control SR[2:0]. All 8 values are valid. 0x0: Fastest .... 0x7: Slowest
  [9:8] DDRCH2_PART5B_WD — PART5B Weak driver control WD[1:0] -For single-ended operation: 0x0: Pull logic is disabled 0x1: Pull-up selected 0x2: Pull-down selected 0x3: Maintain the previous output value -For differential pair operation: 0x0: Pull logic is disabled 0x1: Pull-up selected for padp, pull-down selected for padn 0x2: Pull-down selected for padp, pull-up selected for padn 0x3: Maintain the previous output value
  [7:5] DDRCH2_PART6_I — PART6 Impedence control I[2:0] 0x0: Imp80 0x1: Imp60 0x2: Imp48 0x3: Imp40 0x4: Imp34 0x5: Reserved 0x6: Reserved 0x7: Reserved
  [4:2] DDRCH2_PART6_SR — PART6 Slew Rate control SR[2:0]. All 8 values are valid. 0x0: Fastest .... 0x7: Slowest
  [1:0] DDRCH2_PART6_WD — PART6 Weak driver control WD[1:0] -For single-ended operation: 0x0: Pull logic is disabled 0x1: Pull-up selected 0x2: Pull-down selected 0x3: Maintain the previous output value -For differential pair operation: 0x0: Pull logic is disabled 0x1: Pull-up selected for padp, pull-down selected for padn 0x2: Pull-down selected for padp, pull-up selected for padn 0x3: Maintain the previous output value
0xE38 CTRL_CORE_CONTROL_DDRCH1_0 rw reset 0x4A4A4A4A — DDRCH1 control 0
  [31:29] DDRCH1_PART1A_I — PART1A Impedence control I[2:0] 0x0: Imp80 0x1: Imp60 0x2: Imp48 0x3: Imp40 0x4: Imp34 0x5: Reserved 0x6: Reserved 0x7: Reserved
  [28:26] DDRCH1_PART1A_SR — PART1A Slew Rate control SR[2:0]. All 8 values are valid. 0x0: Fastest .... 0x7: Slowest
  [25:24] DDRCH1_PART1A_WD — PART1A Weak driver control WD[1:0] -For single-ended operation: 0x0: Pull logic is disabled 0x1: Pull-up selected 0x2: Pull-down selected 0x3: Maintain the previous output value -For differential pair operation: 0x0: Pull logic is disabled 0x1: Pull-up selected for padp, pull-down selected for padn 0x2: Pull-down selected for padp, pull-up selected for padn 0x3: Maintain the previous output value
  [23:21] DDRCH1_PART1B_I — PART1B Impedence control I[2:0] 0x0: Imp80 0x1: Imp60 0x2: Imp48 0x3: Imp40 0x4: Imp34 0x5: Reserved 0x6: Reserved 0x7: Reserved
  [20:18] DDRCH1_PART1B_SR — PART1B Slew Rate control SR[2:0]. All 8 values are valid. 0x0: Fastest .... 0x7: Slowest
  [17:16] DDRCH1_PART1B_WD — PART1B Weak driver control WD[1:0] -For single-ended operation: 0x0: Pull logic is disabled 0x1: Pull-up selected 0x2: Pull-down selected 0x3: Maintain the previous output value -For differential pair operation: 0x0: Pull logic is disabled 0x1: Pull-up selected for padp, pull-down selected for padn 0x2: Pull-down selected for padp, pull-up selected for padn 0x3: Maintain the previous output value
  [15:13] DDRCH1_PART2A_I — PART2A Impedence control I[2:0] 0x0: Imp80 0x1: Imp60 0x2: Imp48 0x3: Imp40 0x4: Imp34 0x5: Reserved 0x6: Reserved 0x7: Reserved
  [12:10] DDRCH1_PART2A_SR — PART2A Slew Rate control SR[2:0]. All 8 values are valid. 0x0: Fastest .... 0x7: Slowest
  [9:8] DDRCH1_PART2A_WD — PART2A Weak driver control WD[1:0] -For single-ended operation: 0x0: Pull logic is disabled 0x1: Pull-up selected 0x2: Pull-down selected 0x3: Maintain the previous output value -For differential pair operation: 0x0: Pull logic is disabled 0x1: Pull-up selected for padp, pull-down selected for padn 0x2: Pull-down selected for padp, pull-up selected for padn 0x3: Maintain the previous output value
  [7:5] DDRCH1_PART2B_I — PART2B Impedence control I[2:0] 0x0: Imp80 0x1: Imp60 0x2: Imp48 0x3: Imp40 0x4: Imp34 0x5: Reserved 0x6: Reserved 0x7: Reserved
  [4:2] DDRCH1_PART2B_SR — PART2B Slew Rate control SR[2:0]. All 8 values are valid. 0x0: Fastest .... 0x7: Slowest
  [1:0] DDRCH1_PART2B_WD — PART2B Weak driver control WD[1:0] -For single-ended operation: 0x0: Pull logic is disabled 0x1: Pull-up selected 0x2: Pull-down selected 0x3: Maintain the previous output value -For differential pair operation: 0x0: Pull logic is disabled 0x1: Pull-up selected for padp, pull-down selected for padn 0x2: Pull-down selected for padp, pull-up selected for padn 0x3: Maintain the previous output value
0xE3C CTRL_CORE_CONTROL_DDRCH1_1 rw reset 0x4A4A4A4A — DDRCH1 control 1
  [31:29] DDRCH1_PART3A_I — PART3A Impedence control I[2:0] 0x0: Imp80 0x1: Imp60 0x2: Imp48 0x3: Imp40 0x4: Imp34 0x5: Reserved 0x6: Reserved 0x7: Reserved
  [28:26] DDRCH1_PART3A_SR — PART3A Slew Rate control SR[2:0]. All 8 values are valid. 0x0: Fastest .... 0x7: Slowest
  [25:24] DDRCH1_PART3A_WD — PART3A Weak driver control WD[1:0] -For single-ended operation: 0x0: Pull logic is disabled 0x1: Pull-up selected 0x2: Pull-down selected 0x3: Maintain the previous output value -For differential pair operation: 0x0: Pull logic is disabled 0x1: Pull-up selected for padp, pull-down selected for padn 0x2: Pull-down selected for padp, pull-up selected for padn 0x3: Maintain the previous output value
  [23:21] DDRCH1_PART3B_I — PART3B Impedence control I[2:0] 0x0: Imp80 0x1: Imp60 0x2: Imp48 0x3: Imp40 0x4: Imp34 0x5: Reserved 0x6: Reserved 0x7: Reserved
  [20:18] DDRCH1_PART3B_SR — PART3B Slew Rate control SR[2:0]. All 8 values are valid. 0x0: Fastest .... 0x7: Slowest
  [17:16] DDRCH1_PART3B_WD — PART3B Weak driver control WD[1:0] -For single-ended operation: 0x0: Pull logic is disabled 0x1: Pull-up selected 0x2: Pull-down selected 0x3: Maintain the previous output value -For differential pair operation: 0x0: Pull logic is disabled 0x1: Pull-up selected for padp, pull-down selected for padn 0x2: Pull-down selected for padp, pull-up selected for padn 0x3: Maintain the previous output value
  [15:13] DDRCH1_PART4A_I — PART4A Impedence control I[2:0] 0x0: Imp80 0x1: Imp60 0x2: Imp48 0x3: Imp40 0x4: Imp34 0x5: Reserved 0x6: Reserved 0x7: Reserved
  [12:10] DDRCH1_PART4A_SR — PART4A Slew Rate control SR[2:0]. All 8 values are valid. 0x0: Fastest .... 0x7: Slowest
  [9:8] DDRCH1_PART4A_WD — PART4A Weak driver control WD[1:0] -For single-ended operation: 0x0: Pull logic is disabled 0x1: Pull-up selected 0x2: Pull-down selected 0x3: Maintain the previous output value -For differential pair operation: 0x0: Pull logic is disabled 0x1: Pull-up selected for padp, pull-down selected for padn 0x2: Pull-down selected for padp, pull-up selected for padn 0x3: Maintain the previous output value
  [7:5] DDRCH1_PART4B_I — PART4B Impedence control I[2:0] 0x0: Imp80 0x1: Imp60 0x2: Imp48 0x3: Imp40 0x4: Imp34 0x5: Reserved 0x6: Reserved 0x7: Reserved
  [4:2] DDRCH1_PART4B_SR — PART4B Slew Rate control SR[2:0]. All 8 values are valid. 0x0: Fastest .... 0x7: Slowest
  [1:0] DDRCH1_PART4B_WD — PART4B Weak driver control WD[1:0] -For single-ended operation: 0x0: Pull logic is disabled 0x1: Pull-up selected 0x2: Pull-down selected 0x3: Maintain the previous output value -For differential pair operation: 0x0: Pull logic is disabled 0x1: Pull-up selected for padp, pull-down selected for padn 0x2: Pull-down selected for padp, pull-up selected for padn 0x3: Maintain the previous output value
0xE40 CTRL_CORE_CONTROL_DDRCH2_0 rw reset 0x4A4A4A4A — DDRCH2 control 0
  [31:29] DDRCH2_PART1A_I — PART1A Impedence control I[2:0] 0x0: Imp80 0x1: Imp60 0x2: Imp48 0x3: Imp40 0x4: Imp34 0x5: Reserved 0x6: Reserved 0x7: Reserved
  [28:26] DDRCH2_PART1A_SR — PART1A Slew Rate control SR[2:0]. All 8 values are valid. 0x0: Fastest .... 0x7: Slowest
  [25:24] DDRCH2_PART1A_WD — PART1A Weak driver control WD[1:0] -For single-ended operation: 0x0: Pull logic is disabled 0x1: Pull-up selected 0x2: Pull-down selected 0x3: Maintain the previous output value -For differential pair operation: 0x0: Pull logic is disabled 0x1: Pull-up selected for padp, pull-down selected for padn 0x2: Pull-down selected for padp, pull-up selected for padn 0x3: Maintain the previous output value
  [23:21] DDRCH2_PART1B_I — PART1B Impedence control I[2:0] 0x0: Imp80 0x1: Imp60 0x2: Imp48 0x3: Imp40 0x4: Imp34 0x5: Reserved 0x6: Reserved 0x7: Reserved
  [20:18] DDRCH2_PART1B_SR — PART1B Slew Rate control SR[2:0]. All 8 values are valid. 0x0: Fastest .... 0x7: Slowest
  [17:16] DDRCH2_PART1B_WD — PART1B Weak driver control WD[1:0] -For single-ended operation: 0x0: Pull logic is disabled 0x1: Pull-up selected 0x2: Pull-down selected 0x3: Maintain the previous output value -For differential pair operation: 0x0: Pull logic is disabled 0x1: Pull-up selected for padp, pull-down selected for padn 0x2: Pull-down selected for padp, pull-up selected for padn 0x3: Maintain the previous output value
  [15:13] DDRCH2_PART2A_I — PART2A Impedence control I[2:0] 0x0: Imp80 0x1: Imp60 0x2: Imp48 0x3: Imp40 0x4: Imp34 0x5: Reserved 0x6: Reserved 0x7: Reserved
  [12:10] DDRCH2_PART2A_SR — PART2A Slew Rate control SR[2:0]. All 8 values are valid. 0x0: Fastest .... 0x7: Slowest
  [9:8] DDRCH2_PART2A_WD — PART2A Weak driver control WD[1:0] -For single-ended operation: 0x0: Pull logic is disabled 0x1: Pull-up selected 0x2: Pull-down selected 0x3: Maintain the previous output value -For differential pair operation: 0x0: Pull logic is disabled 0x1: Pull-up selected for padp, pull-down selected for padn 0x2: Pull-down selected for padp, pull-up selected for padn 0x3: Maintain the previous output value
  [7:5] DDRCH2_PART2B_I — PART2B Impedence control I[2:0] 0x0: Imp80 0x1: Imp60 0x2: Imp48 0x3: Imp40 0x4: Imp34 0x5: Reserved 0x6: Reserved 0x7: Reserved
  [4:2] DDRCH2_PART2B_SR — PART2B Slew Rate control SR[2:0]. All 8 values are valid. 0x0: Fastest .... 0x7: Slowest
  [1:0] DDRCH2_PART2B_WD — PART2B Weak driver control WD[1:0] -For single-ended operation: 0x0: Pull logic is disabled 0x1: Pull-up selected 0x2: Pull-down selected 0x3: Maintain the previous output value -For differential pair operation: 0x0: Pull logic is disabled 0x1: Pull-up selected for padp, pull-down selected for padn 0x2: Pull-down selected for padp, pull-up selected for padn 0x3: Maintain the previous output value
0xE44 CTRL_CORE_CONTROL_DDRCH2_1 rw reset 0x4A4A4A4A — DDRCH2 control 1
  [31:29] DDRCH2_PART3A_I — PART3A Impedence control I[2:0] 0x0: Imp80 0x1: Imp60 0x2: Imp48 0x3: Imp40 0x4: Imp34 0x5: Reserved 0x6: Reserved 0x7: Reserved
  [28:26] DDRCH2_PART3A_SR — PART3A Slew Rate control SR[2:0]. All 8 values are valid. 0x0: Fastest .... 0x7: Slowest
  [25:24] DDRCH2_PART3A_WD — PART3A Weak driver control WD[1:0] -For single-ended operation: 0x0: Pull logic is disabled 0x1: Pull-up selected 0x2: Pull-down selected 0x3: Maintain the previous output value -For differential pair operation: 0x0: Pull logic is disabled 0x1: Pull-up selected for padp, pull-down selected for padn 0x2: Pull-down selected for padp, pull-up selected for padn 0x3: Maintain the previous output value
  [23:21] DDRCH2_PART3B_I — PART3B Impedence control I[2:0] 0x0: Imp80 0x1: Imp60 0x2: Imp48 0x3: Imp40 0x4: Imp34 0x5: Reserved 0x6: Reserved 0x7: Reserved
  [20:18] DDRCH2_PART3B_SR — PART3B Slew Rate control SR[2:0]. All 8 values are valid. 0x0: Fastest .... 0x7: Slowest
  [17:16] DDRCH2_PART3B_WD — PART3B Weak driver control WD[1:0] -For single-ended operation: 0x0: Pull logic is disabled 0x1: Pull-up selected 0x2: Pull-down selected 0x3: Maintain the previous output value -For differential pair operation: 0x0: Pull logic is disabled 0x1: Pull-up selected for padp, pull-down selected for padn 0x2: Pull-down selected for padp, pull-up selected for padn 0x3: Maintain the previous output value
  [15:13] DDRCH2_PART4A_I — PART4A Impedence control I[2:0] 0x0: Imp80 0x1: Imp60 0x2: Imp48 0x3: Imp40 0x4: Imp34 0x5: Reserved 0x6: Reserved 0x7: Reserved
  [12:10] DDRCH2_PART4A_SR — PART4A Slew Rate control SR[2:0]. All 8 values are valid. 0x0: Fastest .... 0x7: Slowest
  [9:8] DDRCH2_PART4A_WD — PART4A Weak driver control WD[1:0] -For single-ended operation: 0x0: Pull logic is disabled 0x1: Pull-up selected 0x2: Pull-down selected 0x3: Maintain the previous output value -For differential pair operation: 0x0: Pull logic is disabled 0x1: Pull-up selected for padp, pull-down selected for padn 0x2: Pull-down selected for padp, pull-up selected for padn 0x3: Maintain the previous output value
  [7:5] DDRCH2_PART4B_I — PART4B Impedence control I[2:0] 0x0: Imp80 0x1: Imp60 0x2: Imp48 0x3: Imp40 0x4: Imp34 0x5: Reserved 0x6: Reserved 0x7: Reserved
  [4:2] DDRCH2_PART4B_SR — PART4B Slew Rate control SR[2:0]. All 8 values are valid. 0x0: Fastest .... 0x7: Slowest
  [1:0] DDRCH2_PART4B_WD — PART4B Weak driver control WD[1:0] -For single-ended operation: 0x0: Pull logic is disabled 0x1: Pull-up selected 0x2: Pull-down selected 0x3: Maintain the previous output value -For differential pair operation: 0x0: Pull logic is disabled 0x1: Pull-up selected for padp, pull-down selected for padn 0x2: Pull-down selected for padp, pull-up selected for padn 0x3: Maintain the previous output value
